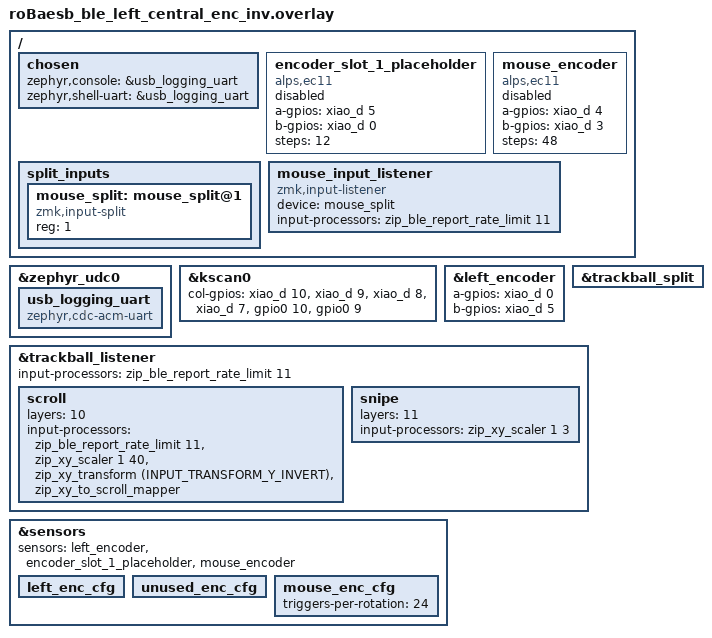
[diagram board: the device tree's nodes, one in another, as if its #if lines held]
#include "../roBa/roBa.dtsi"
#ifdef ZMK_ESB_ADDR_B
#include "roBaesb_addr_b.dtsi"
#else
#include "roBaesb_addr.dtsi"
#endif
#ifdef ZMK_ESB_MOUSE
#include "roBaesb_lariska_transform.dtsi"
#endif

#include <input/processors/xyz.dtsi>
#include <input/processors/report_rate_limit.dtsi>

/ {
    chosen {
        zephyr,console = &usb_logging_uart;
        zephyr,shell-uart = &usb_logging_uart;
    };

#ifdef ZMK_ESB_MOUSE
    /* Positional placeholder only: lariska's encoder reports sensor index 2,
     * so this disabled slot keeps the central keymap array aligned. */
    encoder_slot_1_placeholder: encoder_slot_1_placeholder {
        compatible = "alps,ec11";
        a-gpios = <&xiao_d 5 (GPIO_ACTIVE_HIGH | GPIO_PULL_UP)>;
        b-gpios = <&xiao_d 0 (GPIO_ACTIVE_HIGH | GPIO_PULL_UP)>;
        steps = <12>;
        status = "disabled";
    };

    mouse_encoder: mouse_encoder {
        compatible = "alps,ec11";
        a-gpios = <&xiao_d 4 (GPIO_ACTIVE_HIGH | GPIO_PULL_UP)>;
        b-gpios = <&xiao_d 3 (GPIO_ACTIVE_HIGH | GPIO_PULL_UP)>;
        steps = <48>;
        status = "disabled";
    };

    split_inputs {
        mouse_split: mouse_split@1 {
            compatible = "zmk,input-split";
            reg = <1>;
            status = "okay";
        };
    };

    mouse_input_listener: mouse_input_listener {
        compatible = "zmk,input-listener";
        status = "okay";
        device = <&mouse_split>;
        input-processors = <&zip_ble_report_rate_limit 11>;
    };
#endif
};

&zephyr_udc0 {
    usb_logging_uart: usb_logging_uart {
        compatible = "zephyr,cdc-acm-uart";
    };
};

&kscan0 {
    col-gpios
        = <&xiao_d 10 GPIO_ACTIVE_HIGH>
        , <&xiao_d 9 GPIO_ACTIVE_HIGH>
        , <&xiao_d 8 GPIO_ACTIVE_HIGH>
        , <&xiao_d 7 GPIO_ACTIVE_HIGH>
        , <&gpio0 10 GPIO_ACTIVE_HIGH>
        , <&gpio0 9 GPIO_ACTIVE_HIGH>
        ;
};

/* Inverted encoder: a/b swapped */
&left_encoder {
    a-gpios = <&xiao_d 0 (GPIO_ACTIVE_HIGH | GPIO_PULL_UP)>;
    b-gpios = <&xiao_d 5 (GPIO_ACTIVE_HIGH | GPIO_PULL_UP)>;
    status = "okay";
};

&trackball_split {
    status = "okay";
};

&trackball_listener {
    status = "okay";
    input-processors = <&zip_ble_report_rate_limit 11>;

    scroll {
        layers = <10>;
        input-processors = <&zip_ble_report_rate_limit 11>, <&zip_xy_scaler 1 40>, <&zip_xy_transform (INPUT_TRANSFORM_Y_INVERT)>, <&zip_xy_to_scroll_mapper>;
    };

    snipe {
        layers = <11>;
        input-processors = <&zip_xy_scaler 1 3>;
    };
};

#ifdef ZMK_ESB_MOUSE
&sensors {
    sensors = <&left_encoder &encoder_slot_1_placeholder &mouse_encoder>;
    left_enc_cfg: left_enc_cfg {};
    unused_enc_cfg: unused_enc_cfg {};
    mouse_enc_cfg: mouse_enc_cfg {
        triggers-per-rotation = <24>;
    };
};
#endif
